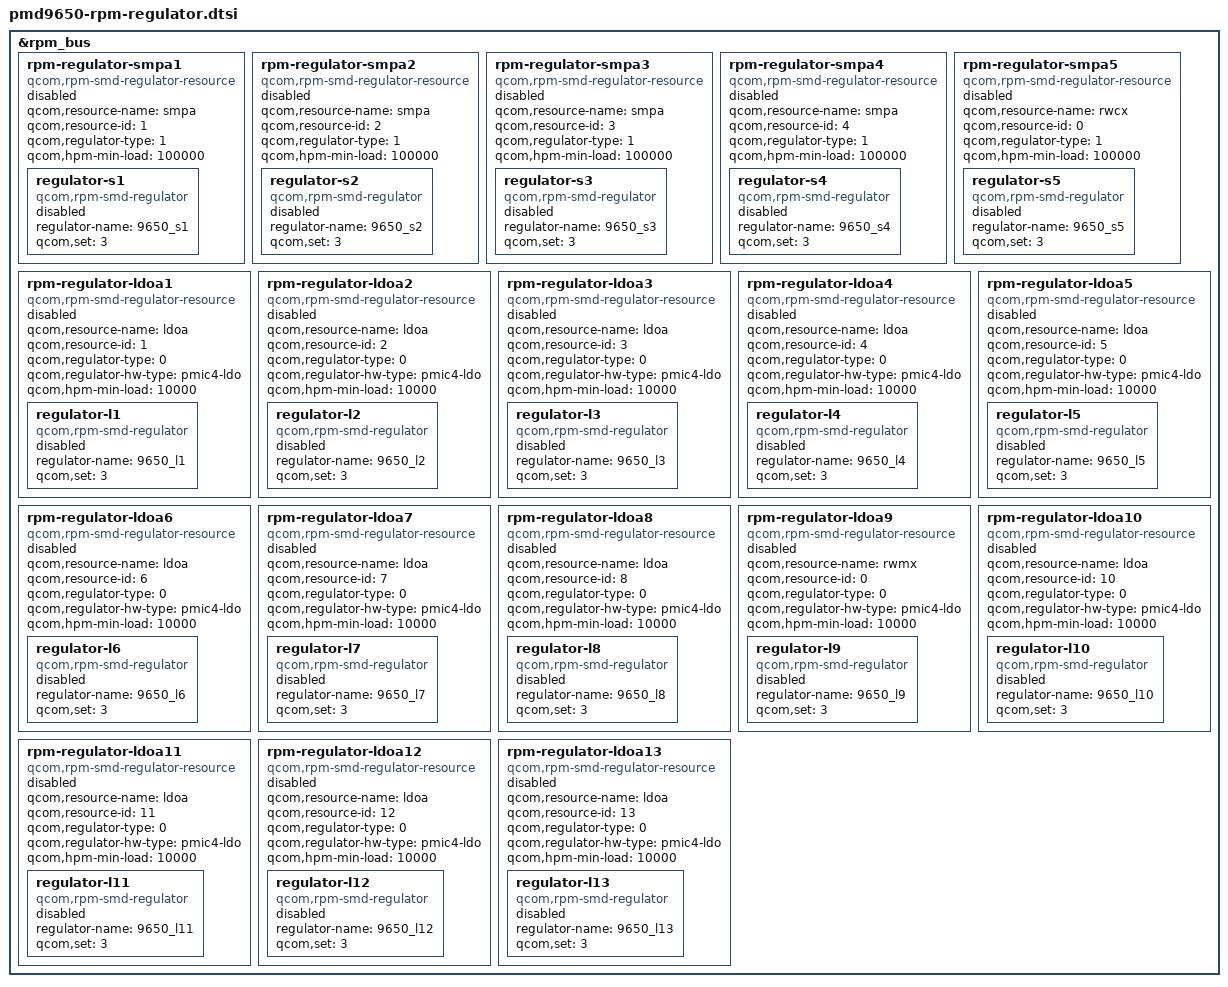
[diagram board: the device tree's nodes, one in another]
&rpm_bus {
	rpm-regulator-smpa1 {
		compatible = "qcom,rpm-smd-regulator-resource";
		qcom,resource-name = "smpa";
		qcom,resource-id = <1>;
		qcom,regulator-type = <1>;
		qcom,hpm-min-load = <100000>;
		status = "disabled";

		regulator-s1 {
			compatible = "qcom,rpm-smd-regulator";
			regulator-name = "9650_s1";
			qcom,set = <3>;
			status = "disabled";
		};
	};

	rpm-regulator-smpa2 {
		compatible = "qcom,rpm-smd-regulator-resource";
		qcom,resource-name = "smpa";
		qcom,resource-id = <2>;
		qcom,regulator-type = <1>;
		qcom,hpm-min-load = <100000>;
		status = "disabled";

		regulator-s2 {
			compatible = "qcom,rpm-smd-regulator";
			regulator-name = "9650_s2";
			qcom,set = <3>;
			status = "disabled";
		};
	};

	rpm-regulator-smpa3 {
		compatible = "qcom,rpm-smd-regulator-resource";
		qcom,resource-name = "smpa";
		qcom,resource-id = <3>;
		qcom,regulator-type = <1>;
		qcom,hpm-min-load = <100000>;
		status = "disabled";

		regulator-s3 {
			compatible = "qcom,rpm-smd-regulator";
			regulator-name = "9650_s3";
			qcom,set = <3>;
			status = "disabled";
		};
	};

	rpm-regulator-smpa4 {
		compatible = "qcom,rpm-smd-regulator-resource";
		qcom,resource-name = "smpa";
		qcom,resource-id = <4>;
		qcom,regulator-type = <1>;
		qcom,hpm-min-load = <100000>;
		status = "disabled";

		regulator-s4 {
			compatible = "qcom,rpm-smd-regulator";
			regulator-name = "9650_s4";
			qcom,set = <3>;
			status = "disabled";
		};
	};

	rpm-regulator-smpa5 {		/* VDD_CX supply */
		compatible = "qcom,rpm-smd-regulator-resource";
		qcom,resource-name = "rwcx";
		qcom,resource-id = <0>;
		qcom,regulator-type = <1>;
		qcom,hpm-min-load = <100000>;
		status = "disabled";

		regulator-s5 {
			compatible = "qcom,rpm-smd-regulator";
			regulator-name = "9650_s5";
			qcom,set = <3>;
			status = "disabled";
		};
	};

	rpm-regulator-ldoa1 {
		compatible = "qcom,rpm-smd-regulator-resource";
		qcom,resource-name = "ldoa";
		qcom,resource-id = <1>;
		qcom,regulator-type = <0>;
		qcom,regulator-hw-type = "pmic4-ldo";
		qcom,hpm-min-load = <10000>;
		status = "disabled";

		regulator-l1 {
			compatible = "qcom,rpm-smd-regulator";
			regulator-name = "9650_l1";
			qcom,set = <3>;
			status = "disabled";
		};
	};

	rpm-regulator-ldoa2 {
		compatible = "qcom,rpm-smd-regulator-resource";
		qcom,resource-name = "ldoa";
		qcom,resource-id = <2>;
		qcom,regulator-type = <0>;
		qcom,regulator-hw-type = "pmic4-ldo";
		qcom,hpm-min-load = <10000>;
		status = "disabled";

		regulator-l2 {
			compatible = "qcom,rpm-smd-regulator";
			regulator-name = "9650_l2";
			qcom,set = <3>;
			status = "disabled";
		};
	};

	rpm-regulator-ldoa3 {
		compatible = "qcom,rpm-smd-regulator-resource";
		qcom,resource-name = "ldoa";
		qcom,resource-id = <3>;
		qcom,regulator-type = <0>;
		qcom,regulator-hw-type = "pmic4-ldo";
		qcom,hpm-min-load = <10000>;
		status = "disabled";

		regulator-l3 {
			compatible = "qcom,rpm-smd-regulator";
			regulator-name = "9650_l3";
			qcom,set = <3>;
			status = "disabled";
		};
	};

	rpm-regulator-ldoa4 {
		compatible = "qcom,rpm-smd-regulator-resource";
		qcom,resource-name = "ldoa";
		qcom,resource-id = <4>;
		qcom,regulator-type = <0>;
		qcom,regulator-hw-type = "pmic4-ldo";
		qcom,hpm-min-load = <10000>;
		status = "disabled";

		regulator-l4 {
			compatible = "qcom,rpm-smd-regulator";
			regulator-name = "9650_l4";
			qcom,set = <3>;
			status = "disabled";
		};
	};

	rpm-regulator-ldoa5 {
		compatible = "qcom,rpm-smd-regulator-resource";
		qcom,resource-name = "ldoa";
		qcom,resource-id = <5>;
		qcom,regulator-type = <0>;
		qcom,regulator-hw-type = "pmic4-ldo";
		qcom,hpm-min-load = <10000>;
		status = "disabled";

		regulator-l5 {
			compatible = "qcom,rpm-smd-regulator";
			regulator-name = "9650_l5";
			qcom,set = <3>;
			status = "disabled";
		};
	};

	rpm-regulator-ldoa6 {
		compatible = "qcom,rpm-smd-regulator-resource";
		qcom,resource-name = "ldoa";
		qcom,resource-id = <6>;
		qcom,regulator-type = <0>;
		qcom,regulator-hw-type = "pmic4-ldo";
		qcom,hpm-min-load = <10000>;
		status = "disabled";

		regulator-l6 {
			compatible = "qcom,rpm-smd-regulator";
			regulator-name = "9650_l6";
			qcom,set = <3>;
			status = "disabled";
		};
	};

	rpm-regulator-ldoa7 {
		compatible = "qcom,rpm-smd-regulator-resource";
		qcom,resource-name = "ldoa";
		qcom,resource-id = <7>;
		qcom,regulator-type = <0>;
		qcom,regulator-hw-type = "pmic4-ldo";
		qcom,hpm-min-load = <10000>;
		status = "disabled";

		regulator-l7 {
			compatible = "qcom,rpm-smd-regulator";
			regulator-name = "9650_l7";
			qcom,set = <3>;
			status = "disabled";
		};
	};

	rpm-regulator-ldoa8 {
		compatible = "qcom,rpm-smd-regulator-resource";
		qcom,resource-name = "ldoa";
		qcom,resource-id = <8>;
		qcom,regulator-type = <0>;
		qcom,regulator-hw-type = "pmic4-ldo";
		qcom,hpm-min-load = <10000>;
		status = "disabled";

		regulator-l8 {
			compatible = "qcom,rpm-smd-regulator";
			regulator-name = "9650_l8";
			qcom,set = <3>;
			status = "disabled";
		};
	};

	rpm-regulator-ldoa9 {		/* VDD_MX supply */
		compatible = "qcom,rpm-smd-regulator-resource";
		qcom,resource-name = "rwmx";
		qcom,resource-id = <0>;
		qcom,regulator-type = <0>;
		qcom,regulator-hw-type = "pmic4-ldo";
		qcom,hpm-min-load = <10000>;
		status = "disabled";

		regulator-l9 {
			compatible = "qcom,rpm-smd-regulator";
			regulator-name = "9650_l9";
			qcom,set = <3>;
			status = "disabled";
		};
	};

	rpm-regulator-ldoa10 {
		compatible = "qcom,rpm-smd-regulator-resource";
		qcom,resource-name = "ldoa";
		qcom,resource-id = <10>;
		qcom,regulator-type = <0>;
		qcom,regulator-hw-type = "pmic4-ldo";
		qcom,hpm-min-load = <10000>;
		status = "disabled";

		regulator-l10 {
			compatible = "qcom,rpm-smd-regulator";
			regulator-name = "9650_l10";
			qcom,set = <3>;
			status = "disabled";
		};
	};

	rpm-regulator-ldoa11 {
		compatible = "qcom,rpm-smd-regulator-resource";
		qcom,resource-name = "ldoa";
		qcom,resource-id = <11>;
		qcom,regulator-type = <0>;
		qcom,regulator-hw-type = "pmic4-ldo";
		qcom,hpm-min-load = <10000>;
		status = "disabled";

		regulator-l11 {
			compatible = "qcom,rpm-smd-regulator";
			regulator-name = "9650_l11";
			qcom,set = <3>;
			status = "disabled";
		};
	};

	rpm-regulator-ldoa12 {
		compatible = "qcom,rpm-smd-regulator-resource";
		qcom,resource-name = "ldoa";
		qcom,resource-id = <12>;
		qcom,regulator-type = <0>;
		qcom,regulator-hw-type = "pmic4-ldo";
		qcom,hpm-min-load = <10000>;
		status = "disabled";

		regulator-l12 {
			compatible = "qcom,rpm-smd-regulator";
			regulator-name = "9650_l12";
			qcom,set = <3>;
			status = "disabled";
		};
	};

	rpm-regulator-ldoa13 {
		compatible = "qcom,rpm-smd-regulator-resource";
		qcom,resource-name = "ldoa";
		qcom,resource-id = <13>;
		qcom,regulator-type = <0>;
		qcom,regulator-hw-type = "pmic4-ldo";
		qcom,hpm-min-load = <10000>;
		status = "disabled";

		regulator-l13 {
			compatible = "qcom,rpm-smd-regulator";
			regulator-name = "9650_l13";
			qcom,set = <3>;
			status = "disabled";
		};
	};
};
